AUTOSAR XML (schema 00048)
package /ComponentTypes
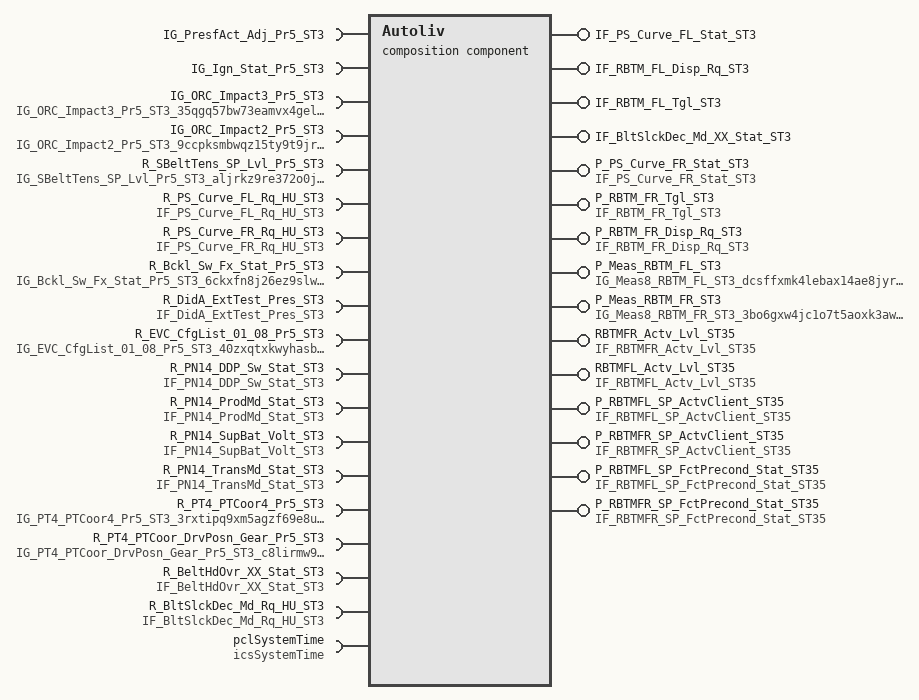
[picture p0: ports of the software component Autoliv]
  composition sw component type Autoliv
    4 x require port:
      IG_PresfAct_Adj_Pr5_ST3: nonqueued-receiver-com-spec{data-element=PresfAct_Adj_Pr5_ST3, filter=data-filter-type=ALWAYS}, required-interface=IG_PresfAct_Adj_Pr5_ST3
      IG_Ign_Stat_Pr5_ST3: nonqueued-receiver-com-spec{data-element=Ign_Stat_Pr5_ST3, filter=data-filter-type=ALWAYS}, required-interface=IG_Ign_Stat_Pr5_ST3
      IG_ORC_Impact3_Pr5_ST3: nonqueued-receiver-com-spec{data-element=ORC_Impact3_Pr5_ST3, filter=data-filter-type=ALWAYS}, required-interface=IG_ORC_Impact3_Pr5_ST3_35qgq57bw73eamvx4gelk7iiv
      IG_ORC_Impact2_Pr5_ST3: nonqueued-receiver-com-spec{data-element=ORC_Impact2_Pr5_ST3, filter=data-filter-type=ALWAYS}, required-interface=IG_ORC_Impact2_Pr5_ST3_9ccpksmbwqz15ty9t9jr7ps1e
    9 x provide port:
      IF_PS_Curve_FL_Stat_ST3: nonqueued-sender-com-spec=PS_Curve_FL_Stat_ST3, provided-interface=IF_PS_Curve_FL_Stat_ST3
      IF_RBTM_FL_Disp_Rq_ST3: nonqueued-sender-com-spec=RBTM_FL_Disp_Rq_ST3, provided-interface=IF_RBTM_FL_Disp_Rq_ST3
      IF_RBTM_FL_Tgl_ST3: nonqueued-sender-com-spec=RBTM_FL_Tgl_ST3, provided-interface=IF_RBTM_FL_Tgl_ST3
      IF_BltSlckDec_Md_XX_Stat_ST3: nonqueued-sender-com-spec=BltSlckDec_Md_XX_Stat_ST3, provided-interface=IF_BltSlckDec_Md_XX_Stat_ST3
      P_PS_Curve_FR_Stat_ST3: nonqueued-sender-com-spec{data-element=PS_Curve_FR_Stat_ST3, init-value=constant-reference=XDIS_7s3506puhms1tg6jklvb6yyln}, provided-interface=IF_PS_Curve_FR_Stat_ST3  # PreSafe Curve mode state front right
      P_RBTM_FR_Tgl_ST3: nonqueued-sender-com-spec{data-element=RBTM_FR_Tgl_ST3, init-value=constant-reference=XDIS_h5tcyk98kzbgrc5svasomeyt}, provided-interface=IF_RBTM_FR_Tgl_ST3  # Presafe Togglebit
      P_RBTM_FR_Disp_Rq_ST3: nonqueued-sender-com-spec{data-element=RBTM_FR_Disp_Rq_ST3, init-value=constant-reference=XDIS_mplw7kqzq1h511zsujiz4bgo}, provided-interface=IF_RBTM_FR_Disp_Rq_ST3  # Presafe display request front right
      P_Meas_RBTM_FL_ST3: nonqueued-sender-com-spec{data-element=Meas8_RBTM_FL_ST3, init-value=constant-reference=XDIS_ckvw3q385offj9s5jhb6jp6cr}, provided-interface=IG_Meas8_RBTM_FL_ST3_dcsffxmk4lebax14ae8jyr2nd  # Measurement (degraded)
      P_Meas_RBTM_FR_ST3: nonqueued-sender-com-spec{data-element=Meas8_RBTM_FR_ST3, init-value=constant-reference=XDIS_byyw7b3ki3w79jkgp9jr5allr}, provided-interface=IG_Meas8_RBTM_FR_ST3_3bo6gxw4jc1o7t5aoxk3awdcy  # Measurement (degraded)
    require port R_SBeltTens_SP_Lvl_Pr5_ST3: nonqueued-receiver-com-spec{data-element=SBeltTens_SP_Lvl_Pr5_ST3, end-to-end-transformation-com-spec-props{disable-end-to-end-check=false, max-delta-counter=3, max-error-state-init=0, max-error-state-invalid=0, max-error-state-valid=0, min-ok-state-init=1, min-ok-state-invalid=1, min-ok-state-valid=1, window-size=10}, alive-timeout=2, init-value=constant-reference=XDIS_4wiqeqoz18rz4k73xcp12oii1}, required-interface=IG_SBeltTens_SP_Lvl_Pr5_ST3_aljrkz9re372o0jtum2i5lh8w  # Seat Belt Tensioner SP Lvl ST3 (degraded)
    provide port RBTMFR_Actv_Lvl_ST35: nonqueued-sender-com-spec=RBTMFR_Actv_Lvl_ST35, provided-interface=IF_RBTMFR_Actv_Lvl_ST35
    provide port RBTMFL_Actv_Lvl_ST35: nonqueued-sender-com-spec=RBTMFL_Actv_Lvl_ST35, provided-interface=IF_RBTMFL_Actv_Lvl_ST35
    require port R_PS_Curve_FL_Rq_HU_ST3: nonqueued-receiver-com-spec{data-element=PS_Curve_FL_Rq_HU_ST3, alive-timeout=10.1, init-value=constant-reference=XDIS_avyye5ls1y4c08a0jv466vs3h}, required-interface=IF_PS_Curve_FL_Rq_HU_ST3  # PreSafe Curve mode request from headunit front left
    require port R_PS_Curve_FR_Rq_HU_ST3: nonqueued-receiver-com-spec{data-element=PS_Curve_FR_Rq_HU_ST3, alive-timeout=10.1, init-value=constant-reference=XDIS_avyye5ls1y4c08a0jv466vs3h}, required-interface=IF_PS_Curve_FR_Rq_HU_ST3  # IF PS Curve front right Request(ed) HU ST3
    4 x provide port:
      P_RBTMFL_SP_ActvClient_ST35: nonqueued-sender-com-spec{data-element=RBTMFL_SP_ActvClient_ST35, init-value=constant-reference=XDIS_ech1daxmjqjqyzrsfliduv3re}, provided-interface=IF_RBTMFL_SP_ActvClient_ST35  # Active seatbelt tensioning request source front left
      P_RBTMFR_SP_ActvClient_ST35: nonqueued-sender-com-spec{data-element=RBTMFR_SP_ActvClient_ST35, init-value=constant-reference=XDIS_ech1daxmjqjqyzrsfliduv3re}, provided-interface=IF_RBTMFR_SP_ActvClient_ST35  # Active seatbelt tensioning request source front right
      P_RBTMFL_SP_FctPrecond_Stat_ST35: nonqueued-sender-com-spec{data-element=RBTMFL_SP_FctPrecond_Stat_ST35, init-value=0}, provided-interface=IF_RBTMFL_SP_FctPrecond_Stat_ST35  # List of unfulfilled preconditions for rev. seatbelt tensioning front left
      P_RBTMFR_SP_FctPrecond_Stat_ST35: nonqueued-sender-com-spec{data-element=RBTMFR_SP_FctPrecond_Stat_ST35, init-value=0}, provided-interface=IF_RBTMFR_SP_FctPrecond_Stat_ST35  # List of unfulfilled preconditions for rev. seatbelt tensioning front right
    12 x require port:
      R_Bckl_Sw_Fx_Stat_Pr5_ST3: nonqueued-receiver-com-spec{data-element=Bckl_Sw_Fx_Stat_Pr5_ST3, end-to-end-transformation-com-spec-props{disable-end-to-end-check=false, max-delta-counter=3, max-error-state-init=0, max-error-state-invalid=0, max-error-state-valid=0, min-ok-state-init=1, min-ok-state-invalid=1, min-ok-state-valid=1, window-size=10}, init-value=constant-reference=XDIS_by5k2ulzqy4hav7734lki195k}, required-interface=IG_Bckl_Sw_Fx_Stat_Pr5_ST3_6ckxfn8j26ez9slws8s7zuact  # Bckl Sw Fx state ST3 (degraded)
      R_DidA_ExtTest_Pres_ST3: nonqueued-receiver-com-spec{data-element=DidA_ExtTest_Pres_ST3, init-value=constant-reference=XDIS_f4mtuwvd3r353o80f6rps7w7}, required-interface=IF_DidA_ExtTest_Pres_ST3  # DidA external tester present
      R_EVC_CfgList_01_08_Pr5_ST3: nonqueued-receiver-com-spec{data-element=EVC_CfgList_01_08_Pr5_ST3, end-to-end-transformation-com-spec-props=disable-end-to-end-check=true, alive-timeout=2.5, init-value=constant-reference=XDIS_7tqm5jy9oba0thvws62i3l28n}, required-interface=IG_EVC_CfgList_01_08_Pr5_ST3_40zxqtxkwyhasb66rr3qexjf2  # EVC Cfg List 01 08 Pr 5 ST3 (degraded)
      R_PN14_DDP_Sw_Stat_ST3: nonqueued-receiver-com-spec{data-element=PN14_DDP_Sw_Stat_ST3, init-value=constant-reference=XDIS_c8apwmaohcx1gxigvciebloy2}, required-interface=IF_PN14_DDP_Sw_Stat_ST3  # Deep discharge protection switch state
      R_PN14_ProdMd_Stat_ST3: nonqueued-receiver-com-spec{data-element=PN14_ProdMd_Stat_ST3, init-value=constant-reference=XDIS_4um78o9kgep1cp3dhn51ycc2o}, required-interface=IF_PN14_ProdMd_Stat_ST3  # Powernet production mode state
      R_PN14_SupBat_Volt_ST3: nonqueued-receiver-com-spec{data-element=PN14_SupBat_Volt_ST3, init-value=constant-reference=XDIS_9jzhpgyeg4j2n16k3jmfeesjo}, required-interface=IF_PN14_SupBat_Volt_ST3  # Supply battery voltage
      R_PN14_TransMd_Stat_ST3: nonqueued-receiver-com-spec{data-element=PN14_TransMd_Stat_ST3, init-value=constant-reference=XDIS_18rb2bxx4r5d75figzrcw50gp}, required-interface=IF_PN14_TransMd_Stat_ST3  # Powernet transport mode status
      R_PT4_PTCoor4_Pr5_ST3: nonqueued-receiver-com-spec{data-element=PT4_PTCoor4_Pr5_ST3, end-to-end-transformation-com-spec-props=disable-end-to-end-check=true, alive-timeout=1.05, init-value=constant-reference=XDIS_9h6oqehaueepowg2tijus0mir}, required-interface=IG_PT4_PTCoor4_Pr5_ST3_3rxtipq9xm5agzf69e8usehmj  # PT4_PTCoor4_Pr5_ST3 (degraded)
      R_PT4_PTCoor_DrvPosn_Gear_Pr5_ST3: nonqueued-receiver-com-spec{data-element=PT4_PTCoor_DrvPosn_Gear_Pr5_ST3, end-to-end-transformation-com-spec-props=disable-end-to-end-check=true, init-value=constant-reference=XDIS_8ocy3iwo1ditemd6qwphg7b7i}, required-interface=IG_PT4_PTCoor_DrvPosn_Gear_Pr5_ST3_c8lirmw9wm5odas0h648yyd4w  # PT4 PT Coor Drv position Gear Pr 5 ST3 (degraded)
      R_BeltHdOvr_XX_Stat_ST3: nonqueued-receiver-com-spec{data-element=BeltHdOvr_XX_Stat_ST3, alive-timeout=5.25, init-value=constant-reference=XDIS_9pu33xhskzhvc3a6idhpuk7uh}, required-interface=IF_BeltHdOvr_XX_Stat_ST3  # Belt hand over state
      R_BltSlckDec_Md_Rq_HU_ST3: nonqueued-receiver-com-spec{data-element=BltSlckDec_Md_Rq_HU_ST3, init-value=constant-reference=XDIS_1vei4uht6zuq0e57z2qtds6y7}, required-interface=IF_BltSlckDec_Md_Rq_HU_ST3
      pclSystemTime: required-com-specs=[ReadRelativeSystemTime, WriteRelativeSystemTime, ReadAbsoluteSystemTime, WriteAbsoluteSystemTime], required-interface=icsSystemTime
    18 x component:
      CIL: type=CIL_AC_CommunicationInteractionLayer
      BFE: type=BFE_AC_BeltFunctionExecution
      BFS: type=BFS_AC_BeltFunctionSelection
      PRE: type=PRE_AC_PreTensioning
      SFR: type=SFR_AC_StandardFunctionRecovery
      MMG: type=MMG_AC_ModeManagement
      DIA: type=DIA_AC_DiagOnCAN
      PMP: type=PMP_AC_PhysicalMeasuresProvider
      PAL: type=PAL_AC_PowerAbstractionLayer
      HWA: type=HWA_AC_HapticWarning
      EOL: type=EOL_AC_EndOfLifeManagement
      BSR: type=BSR_AC_BeltSlackReduction
      RCM: type=RCM_AC_ResetCauseManagement
      ATM: type=ATM_AC_AutoTestManager
      ERH: type=ERH_AC_ErrorHandler
      PRO: type=PRO_AC_ProductionCycles
      BMM: type=BMM_AC_BeltMovementMonitoring
      SCM: type=SCM_AC_SystemContextManagement
    delegate CIL.IF_BltSlckDec_Md_XX_Stat_ST3 <-> outer port IF_BltSlckDec_Md_XX_Stat_ST3
    delegate CIL.IF_PS_Curve_FL_Stat_ST3 <-> outer port IF_PS_Curve_FL_Stat_ST3
    delegate CIL.IF_RBTM_FL_Disp_Rq_ST3 <-> outer port IF_RBTM_FL_Disp_Rq_ST3
    delegate CIL.IF_RBTM_FL_Tgl_ST3 <-> outer port IF_RBTM_FL_Tgl_ST3
    delegate CIL.IG_Ign_Stat_Pr5_ST3 <-> outer port IG_Ign_Stat_Pr5_ST3
    delegate CIL.IG_ORC_Impact2_Pr5_ST3 <-> outer port IG_ORC_Impact2_Pr5_ST3
    delegate CIL.IG_ORC_Impact3_Pr5_ST3 <-> outer port IG_ORC_Impact3_Pr5_ST3
    delegate CIL.IG_PresfAct_Adj_Pr5_ST3 <-> outer port IG_PresfAct_Adj_Pr5_ST3
    connect CIL.psrCustomerSpecific -> BFE.prrCustomerSpecific
    connect BFS.psrSelectedCycle -> CIL.prrSelectedCycle
    connect BFS.psrSelectedCycle -> BFE.prrSelectedCycle
    connect BFE.psrExecutedCycle -> BFS.prrExecutedCycle
    connect BFE.psrExecutedCycle -> CIL.prrCycleNumber
    connect BFE.psrExecutedStep -> CIL.prrStepNumber
    connect BFE.psrExecutedCycle -> PRE.prrExecutedCycle
    connect CIL.psrCustomerSpecific -> PRE.prrCustomerSpecific
    connect PRE.psrAlgo_Flags_PRE1 -> BFS.prrAlgo01_Flags
    connect PRE.psrAlgo_Flags_PRE2 -> BFS.prrAlgo02_Flags
    connect CIL.psrCustomerSpecific -> SFR.prrCustomerSpecific
    connect BFE.psrExecutedCycle -> SFR.prrExecutedCycle
    connect MMG.pseModeManagement -> CIL.pclModeManagement
    connect MMG.pseModeManagement -> PRE.pclModeManagement
    connect MMG.pseModeManagement -> SFR.pclModeManagement
    connect CIL.psrCustomerSpecific -> MMG.prrCustomerSpecific
    connect BFE.psrExecutedCycle -> MMG.prrExecutedCycle
    connect SFR.psrBeltStackAntipatina -> CIL.prrBeltStackAntipatina
    connect BFE.psrExecutedCycle -> DIA.prrExecutedCycle
    connect PRE.psrTrigOFF -> BFE.prrCarAcceleration
    connect CIL.psrCarAcceleration -> PRE.prrGlobalCarAcceleration
    connect CIL.psrCarAcceleration -> SFR.prrCarAcceleration
    connect CIL.prrCrashSeverityLevel -> PRE.prrPreCrashSeverityLevel
    connect PAL.pseMotor_P -> BFE.pclMotor_P
    connect PMP.pseMotor_R -> BFE.pclMotor_R
    connect PMP.pseKL30_V -> BFE.pclKL30_V
    connect PMP.pseECUT_T -> BFE.pclECU_T
    connect PAL.psvMotor_I -> PMP.pclMotor_I
    connect PAL.psvMotor_I -> BFE.pclMotor_I
    connect PMP.psvMotor_T -> PAL.pclMotor_T
    delegate CIL.P_PS_Curve_FR_Stat_ST3 <-> outer port P_PS_Curve_FR_Stat_ST3
    delegate CIL.P_RBTM_FR_Disp_Rq_ST3 <-> outer port P_RBTM_FR_Disp_Rq_ST3
    delegate CIL.P_RBTM_FR_Tgl_ST3 <-> outer port P_RBTM_FR_Tgl_ST3
    connect MMG.psrEnableCycle0 -> CIL.prrEnableCycle0
    connect MMG.psrEnableCycle1 -> CIL.prrEnableCycle1
    delegate CIL.P_Meas_RBTM_FL_ST3 <-> outer port P_Meas_RBTM_FL_ST3
    delegate CIL.P_Meas_RBTM_FR_ST3 <-> outer port P_Meas_RBTM_FR_ST3
    connect PRE.psrAlgo_Flags_PRE3 -> BFS.prrAlgo03_Flags
    connect PRE.psrAlgo_Flags_PRE4 -> BFS.prrAlgo04_Flags
    connect MMG.pseModeManagement -> BSR.pclModeManagement
    connect CIL.psrCustomerSpecific -> BSR.prrCustomerSpecific
    connect BFE.psrExecutedCycle -> BSR.prrExecutedCycle
    connect MMG.pseModeManagement -> HWA.pclModeManagement
    connect CIL.psrCustomerSpecific -> HWA.prrCustomerSpecific
    connect BFE.psrExecutedCycle -> HWA.prrExecutedCycle
    connect CIL.psrCustomerSpecific -> EOL.prrCustomerSpecific
    connect BFE.psrExecutedCycle -> EOL.prrExecutedCycle
    connect BFE.psrExecutedStep -> EOL.prrExecutedStep
    connect RCM.pseResetCause -> MMG.pclResetCause
    connect CIL.psrBuckleDoorSwitch -> BSR.prrBuckleDoorSwitch
    connect BFE.psrExecutedCycle -> PAL.prrExecutedCycle
    connect PAL.pseMotor_P -> CIL.pclMotor_P
    connect PAL.pseMotor_P -> PMP.pclMotor_P
    connect PAL.psvMotor_I -> CIL.pclMotor_I
    connect PMP.pseECUT_T -> CIL.pclECU_T
    connect PMP.pseECUT_T -> PAL.pclECU_T
    connect PMP.pseECU_R -> BFE.pclECU_R
    connect PMP.pseGND_V -> PAL.pclGND_V
    connect PMP.pseGND_V -> CIL.pclGND_V
    connect PMP.pseHS1_V -> CIL.pclHS1_V
    connect PMP.pseHS1_V -> PAL.pclHS1_V
    connect PMP.pseMotor_Vn -> CIL.pclMotor_Vn
    connect PMP.pseMotor_Vn -> PAL.pclMotor_Vn
    connect PMP.pseMotor_Vp -> CIL.pclMotor_Vp
    connect PMP.pseMotor_Vp -> PAL.pclMotor_Vp
    connect PMP.pseREFCpuReg_V -> CIL.pclREFCpuReg_V
    connect PMP.pseREFHigh_V -> CIL.pclREFHigh_V
    connect PMP.pseREFMid_V -> CIL.pclREFMid_V
    connect PMP.pseKL30_V -> CIL.pclKL30_V
    connect PMP.psvCheckPowerSupplyUV -> CIL.pclAutoTestCheckPowerUV
    connect MMG.pseModeManagement -> PAL.pclModeManagement
    connect PMP.pseMotor_R -> PAL.pclResistance
    connect PMP.pseKL30_V -> PAL.pclKL30_V
    connect MMG.pseModeManagement -> ATM.pclModeManagement
    connect RCM.pseRunExtWDTest -> ATM.pclRunExtWatchogTest
    connect PAL.pseCheckMotorSC -> ATM.pclCheckMotorSC
    connect PAL.pseCheckCommandConsistency -> ATM.pclCheckCommandConsistency
    connect PAL.pseCheckHighSideSWRegulation -> ATM.pclCheckHighSideSwRegulation
    connect PAL.pseCheckHWSelfProtection -> ATM.pclCheckHWSelfProtection
    connect PAL.pseCheckMosfetHighSC -> ATM.pclCheckMosfetHighSC
    connect PAL.pseCheckMosfetLowSC -> ATM.pclCheckMosfetLowSC
    connect PAL.pseCheckMosfetOCAT -> ATM.pclCheckMosfetOCAT
    connect PAL.pseCheckMotorConnection -> ATM.pclCheckMotorConnection
    connect PAL.pseCheckMotorDisengagement -> ATM.pclCheckMotorDisengagement
    connect PAL.pseCheckMotorPowerOrder -> ATM.pclCheckMotorPowerOrder
    connect PAL.pseCheckMotorCurrent -> ATM.pclCheckMotorCurrent
    connect PAL.pseCheckMotorThermalProctection -> ATM.pclCheckMotorThermalProctection
    connect PMP.psvCheckPowerSupplyUVDuringActivation -> ATM.pclCheckPowerSupplyUVDuringActivation
    connect PMP.psvCheckPowerSupplyUV -> ATM.pclCheckPowerSupplyUV
    connect PMP.psvCheckPowerSupplyOV -> ATM.pclCheckPowerSupplyOV
    connect PMP.pseCheckTemperatureSensor -> ATM.pclCheckTemperatureSensor
    connect EOL.pseCheckProductEndOfLifeComfort -> ATM.pclCheckProductEndOfLifeComfort
    connect EOL.pseCheckProductEndOfLifeHighForce -> ATM.pclCheckProductEndOfLifeHighForce
    connect EOL.pseCheckProductEndOfLifeLowForce -> ATM.pclCheckProductEndOfLifeLowForce
    connect EOL.pseCheckProductEndOfLifeMaxForce -> ATM.pclCheckProductEndOfLifeMaxForce
    connect RCM.pseRunResetCause -> ATM.pclRunResetCause
    connect PMP.psvCheckPowerSupplyOVDuringActivation -> ATM.pclCheckPowerSupplyOVDuringActivation
    connect MMG.pseModeManagement -> PRO.pclModeManagement
    connect BFE.psrExecutedCycle -> PRO.prrExecutedCycle
    connect ATM.pseAutotestServices -> BSR.pclAutotestServices
    connect ATM.pseAutotestServices -> CIL.pclAutotestServices
    connect ATM.pseAutotestServices -> HWA.pclAutotestServices
    connect ATM.pseAutotestServices -> PAL.pclAutotestServices
    connect ATM.pseAutotestServices -> PMP.pclAutotestServices
    connect ATM.pseAutotestServices -> PRE.pclAutotestServices
    connect ATM.pseAutotestServices -> PRO.pclAutotestServices
    connect ATM.pseAutotestServices -> SFR.pclAutotestServices
    connect ERH.pseAecStatus -> ATM.pclAecStatus
    connect ERH.pseAecStatus -> BFE.pclAecStatus
    connect ERH.pseAecStatus -> BSR.pclAecStatus
    connect ERH.pseAecStatus -> CIL.pclAecStatus
    connect ERH.pseAecStatus -> DIA.pclAecStatus
    connect ERH.pseAecStatus -> HWA.pclAecStatus
    connect ERH.pseAecStatus -> MMG.pclAecStatus
    connect ERH.pseAecStatus -> PAL.pclAecStatus
    connect ERH.pseAecStatus -> PMP.pclAecStatus
    connect ERH.pseAecStatus -> PRE.pclAecStatus
    connect ERH.pseAecStatus -> PRO.pclAecStatus
    connect ERH.pseAecStatus -> RCM.pclAecStatus
    connect ERH.pseAecStatus -> SFR.pclAecStatus
    connect PMP.psvMotor_T -> CIL.pclMotor_T
    connect DIA.pseDiagRequestCycle -> BSR.pclDiagRequestCycle
    connect DIA.pseDiagRequestCycle -> HWA.pclDiagRequestCycle
    connect DIA.pseDiagRequestCycle -> PRE.pclDiagRequestCycle
    connect DIA.pseDiagRequestCycle -> PRO.pclDiagRequestCycle
    connect DIA.pseDiagRequestCycle -> SFR.pclDiagRequestCycle
    connect MMG.pseModeManagement -> PMP.pclModeManagement
    connect ATM.pseAutotestServices -> BMM.pclAutotestServices
    connect MMG.pseModeManagement -> BMM.pclModeManagement
    connect BMM.pseBelt_D -> BFE.pclBelt_D
    connect BMM.pseBelt_D -> BSR.pclBelt_D
    connect BMM.pseBelt_D -> CIL.pclBelt_D
    connect BMM.pseBelt_S -> BFE.pseBelt_S
    connect BMM.pseBelt_S -> CIL.pclBelt_S
    connect BMM.pseCheckHallEffectSensor -> ATM.pclCheckHallEffectSensor
    connect BMM.pseHBSControl -> MMG.pcl_HBSControl
    connect BMM.psePyroDevice -> CIL.pclPyroDevice
    connect BMM.psePyroDevice -> MMG.pclPyroDevice
    connect PMP.pseSurveyBatteryVoltage -> MMG.pclSurveyBatteryVoltage
    connect PMP.pseSurveyBatteryVoltage -> PAL.pclSurveyBatteryVoltage
    connect ATM.pseAutotestServices -> MMG.pclAutotestServices
    connect HWA.psrAlgo_Flags_HWA10 -> BFS.prrAlgo19_Flags
    connect HWA.psrAlgo_Flags_HWA11 -> BFS.prrAlgo20_Flags
    connect SFR.psrAlgo_Flags_SMO -> BFS.prrAlgo30_Flags
    connect SFR.psrAlgo_Flags_HRD -> BFS.prrAlgo31_Flags
    connect SFR.psrAlgo_Flags_BCK -> BFS.prrAlgo32_Flags
    connect SFR.psrAlgo_Flags_PAT -> BFS.prrAlgo33_Flags
    connect PRO.psrAlgo_Flags_PRO1 -> BFS.prrAlgo34_Flags
    connect PRO.psrAlgo_Flags_PRO2 -> BFS.prrAlgo35_Flags
    connect MMG.psrEnableCycle3 -> CIL.prrEnableCycle3
    connect MMG.psrEnableCycle2 -> CIL.prrEnableCycle2
    delegate CIL.R_SBeltTens_SP_Lvl_Pr5_ST3 <-> outer port R_SBeltTens_SP_Lvl_Pr5_ST3
    delegate CIL.RBTMFL_Actv_Lvl_ST35 <-> outer port RBTMFL_Actv_Lvl_ST35
    delegate CIL.RBTMFR_Actv_Lvl_ST35 <-> outer port RBTMFR_Actv_Lvl_ST35
    delegate CIL.R_PS_Curve_FL_Rq_HU_ST3 <-> outer port R_PS_Curve_FL_Rq_HU_ST3
    delegate CIL.R_PS_Curve_FR_Rq_HU_ST3 <-> outer port R_PS_Curve_FR_Rq_HU_ST3
    delegate CIL.P_RBTMFR_SP_ActvClient_ST35 <-> outer port P_RBTMFR_SP_ActvClient_ST35
    delegate CIL.P_RBTMFL_SP_ActvClient_ST35 <-> outer port P_RBTMFL_SP_ActvClient_ST35
    delegate CIL.P_RBTMFL_SP_FctPrecond_Stat_ST35 <-> outer port P_RBTMFL_SP_FctPrecond_Stat_ST35
    delegate CIL.P_RBTMFR_SP_FctPrecond_Stat_ST35 <-> outer port P_RBTMFR_SP_FctPrecond_Stat_ST35
    connect PRE.psrAlgo_Flags_PRE15 -> BFS.prrAlgo15_Flags
    delegate CIL.R_Bckl_Sw_Fx_Stat_Pr5_ST3 <-> outer port R_Bckl_Sw_Fx_Stat_Pr5_ST3
    connect DIA.pseDiagRequestCycle -> CIL.pclDiagRequestCycle
    connect MMG.psrEnableCycle18 -> CIL.prrEnableCycle18
    connect MMG.psrEnableCycle19 -> CIL.prrEnableCycle19
    connect MMG.psrEnableCycle14 -> CIL.prrEnableCycle14
    connect ERH.pseAecStatus -> BMM.pclAECStatus
    connect DIA.psePresafeDisplay -> CIL.prrPresafeDisplay
    connect PMP.pseKL30_V -> MMG.pclKL30
    connect PMP.pseECUT_T -> MMG.pclECUT_T
    connect CIL.psePreSafeRecInput -> MMG.pclPreSafeRecInput
    delegate DIA.IG_Ign_Stat_Pr5_ST3_46s203zrl2qg54zbkbmirlx2b <-> outer port IG_Ign_Stat_Pr5_ST3
    delegate DIA.IG_Bckl_Sw_Fx_Stat_Pr5_ST3_6ckxfn8j26ez9slws8s7zuact <-> outer port R_Bckl_Sw_Fx_Stat_Pr5_ST3
    delegate DIA.IG_PresfAct_Adj_Pr5_ST3_863uuptg5wch3t7i31c8crpa2 <-> outer port IG_PresfAct_Adj_Pr5_ST3
    delegate DIA.IG_ORC_Impact3_Pr5_ST3_35qgq57bw73eamvx4gelk7iiv <-> outer port IG_ORC_Impact3_Pr5_ST3
    delegate DIA.IG_SBeltTens_SP_Lvl_Pr5_ST3_aljrkz9re372o0jtum2i5lh8w <-> outer port R_SBeltTens_SP_Lvl_Pr5_ST3
    delegate DIA.IF_DidA_ExtTest_Pres_ST3 <-> outer port R_DidA_ExtTest_Pres_ST3
    delegate DIA.IG_PT4_PTCoor4_Pr5_ST3_3rxtipq9xm5agzf69e8usehmj <-> outer port R_PT4_PTCoor4_Pr5_ST3
    delegate DIA.IF_PN14_SupBat_Volt_ST3 <-> outer port R_PN14_SupBat_Volt_ST3
    delegate DIA.IF_PN14_ProdMd_Stat_ST3 <-> outer port R_PN14_ProdMd_Stat_ST3
    delegate DIA.IF_PN14_DDP_Sw_Stat_ST3 <-> outer port R_PN14_DDP_Sw_Stat_ST3
    delegate DIA.IG_EVC_CfgList_01_08_Pr5_ST3_40zxqtxkwyhasb66rr3qexjf2 <-> outer port R_EVC_CfgList_01_08_Pr5_ST3
    delegate DIA.IG_PT4_PTCoor_DrvPosn_Gear_Pr5_ST3_c8lirmw9wm5odas0h648yyd4w <-> outer port R_PT4_PTCoor_DrvPosn_Gear_Pr5_ST3
    delegate DIA.IF_PN14_TransMd_Stat_ST3 <-> outer port R_PN14_TransMd_Stat_ST3
    delegate DIA.IF_BeltHdOvr_XX_Stat_ST3 <-> outer port R_BeltHdOvr_XX_Stat_ST3
    delegate DIA.R_BltSlckDec_Md_Rq_HU_ST3 <-> outer port R_BltSlckDec_Md_Rq_HU_ST3
    connect MMG.psrEnableCycle4 -> CIL.prrEnableCycle4
    connect MMG.psrEnableCycle17 -> CIL.prrEnableCycle17
    connect MMG.psrEnableCycle10 -> CIL.prrEnableCycle10
    connect MMG.psrEnableCycle7 -> CIL.prrEnableCycle7
    connect MMG.psrEnableCycle16 -> CIL.prrEnableCycle16
    connect MMG.psrEnableCycle6 -> CIL.prrEnableCycle6
    connect MMG.psrEnableCycle11 -> CIL.prrEnableCycle11
    connect MMG.psrEnableCycle15 -> CIL.prrEnableCycle15
    connect MMG.psrEnableCycle13 -> CIL.prrEnableCycle13
    connect MMG.psrEnableCycle9 -> CIL.prrEnableCycle9
    connect MMG.psrEnableCycle12 -> CIL.prrEnableCycle12
    connect MMG.psrEnableCycle8 -> CIL.prrEnableCycle8
    connect MMG.psrEnableCycle5 -> CIL.prrEnableCycle5
    connect PRE.psrAlgo_Flags_PRE10 -> BFS.prrAlgo10_Flags
    connect PRE.psrAlgo_Flags_PRE6 -> BFS.prrAlgo06_Flags
    connect PRE.psrAlgo_Flags_PRE12 -> BFS.prrAlgo12_Flags
    connect PRE.psrAlgo_Flags_PRE5 -> BFS.prrAlgo05_Flags
    connect PRE.psrAlgo_Flags_PRE14 -> BFS.prrAlgo14_Flags
    connect PRE.psrAlgo_Flags_PRE7 -> BFS.prrAlgo07_Flags
    connect PRE.psrAlgo_Flags_PRE13 -> BFS.prrAlgo13_Flags
    connect PRE.psrAlgo_Flags_PRE17 -> BFS.prrAlgo17_Flags
    connect PRE.psrAlgo_Flags_PRE8 -> BFS.prrAlgo08_Flags
    connect PRE.psrAlgo_Flags_PRE11 -> BFS.prrAlgo11_Flags
    connect PRE.psrAlgo_Flags_PRE9 -> BFS.prrAlgo09_Flags
    connect PRE.psrAlgo_Flags_PRE18 -> BFS.prrAlgo18_Flags
    connect PRE.psrAlgo_Flags_PRE16 -> BFS.prrAlgo16_Flags
    connect CIL.psrCustomerSpecific -> PMP.prrCustomerSpecific
    delegate PMP.R_PN14_SupBat_Volt_ST3 <-> outer port R_PN14_SupBat_Volt_ST3
    delegate CIL.R_PT4_PTCoor_DrvPosn_Gear_Pr5_ST3 <-> outer port R_PT4_PTCoor_DrvPosn_Gear_Pr5_ST3
    delegate CIL.R_PT4_PTCoor4_Pr5_ST3 <-> outer port R_PT4_PTCoor4_Pr5_ST3
    delegate CIL.R_EVC_CfgList_01_08_Pr5_ST3 <-> outer port R_EVC_CfgList_01_08_Pr5_ST3
    delegate CIL.R_BeltHdOvr_XX_Stat_ST3 <-> outer port R_BeltHdOvr_XX_Stat_ST3
    connect PMP.psvMotor_T -> MMG.pclMotor_T
    connect CIL.psrPreSafeLvl -> EOL.prrPreSafeLvl
    connect BMM.psePyroDevice -> SCM.pclPyroDevice
    connect RCM.pseResetCause -> SCM.pclResetCause
    connect RCM.pseResetCauseNotification -> SCM.pclResetCauseNotification
    connect BFE.psrExecutedCycle -> SCM.prrExecutedCycle
    delegate CIL.R_BltSlckDec_Md_Rq_HU_ST3 <-> outer port R_BltSlckDec_Md_Rq_HU_ST3
    connect MMG.psrEnableCycle{20..28} -> CIL.prrEnableCycle{20..28}
    connect HWA.psrAlgo_Flags_HWA20 -> BFS.prrAlgo21_Flags
    connect HWA.psrAlgo_Flags_HWA21 -> BFS.prrAlgo22_Flags
    connect HWA.psrAlgo_Flags_HWA30 -> BFS.prrAlgo23_Flags
    connect HWA.psrAlgo_Flags_HWA31 -> BFS.prrAlgo24_Flags
    connect HWA.psrAlgo_Flags_HWA40 -> BFS.prrAlgo25_Flags
    connect HWA.psrAlgo_Flags_HWA41 -> BFS.prrAlgo26_Flags
    connect PRE.psrAlgo_Flags_BSR1 -> BFS.prrAlgo27_Flags
    connect PRE.psrAlgo_Flags_BSR2 -> BFS.prrAlgo28_Flags
    connect PRE.psrAlgo_Flags_BSR3 -> BFS.prrAlgo29_Flags
    connect SCM.pseSystemContextManagement -> MMG.pclSystemContextManagement
    connect SCM.pseSystemContextManagement -> RCM.pclStartupSystemContext
    connect SCM.pseSystemContextManagement -> SFR.pclSystemContextManagement
    connect PMP.psvMotor_T -> SCM.pclMotor_T
    connect BSR.psrAlgo_Flags_BSR -> PRE.prrAlgo27_Flags
    connect CIL.IF_BltSlckDec_Md_XX_Stat_ST3 -> DIA.IF_BltSlckDec_Md_XX_Stat_ST3
    connect EOL.pseExecutionCounterBlockStatus -> MMG.prrExecutionCountersBlockStatus
    connect CIL.psrCANInputBlockStatus -> MMG.prrCANInputBlockStatus
    connect ERH.psrAECsBlockStatus -> MMG.prrAECsBlockStatus
    delegate SCM.pclSystemTime <-> outer port pclSystemTime
    connect SFR.psrAlgo_Flags_SMO -> SCM.prrAlgo30_Flags
    connect SFR.psrAlgo_Flags_HRD -> SCM.prrAlgo31_Flags
    connect SFR.psrAlgo_Flags_BCK -> SCM.prrAlgo32_Flags
    connect SFR.psrAlgo_Flags_PAT -> SCM.prrAlgo33_Flags
    connect MMG.pseModeManagement -> SCM.pclModeManagement
    connect ERH.pseAecStatus -> SCM.pclAecStatus
    delegate CIL.R_PN14_TransMd_Stat_ST3 <-> outer port R_PN14_TransMd_Stat_ST3
    delegate CIL.R_PN14_ProdMd_Stat_ST3 <-> outer port R_PN14_ProdMd_Stat_ST3
